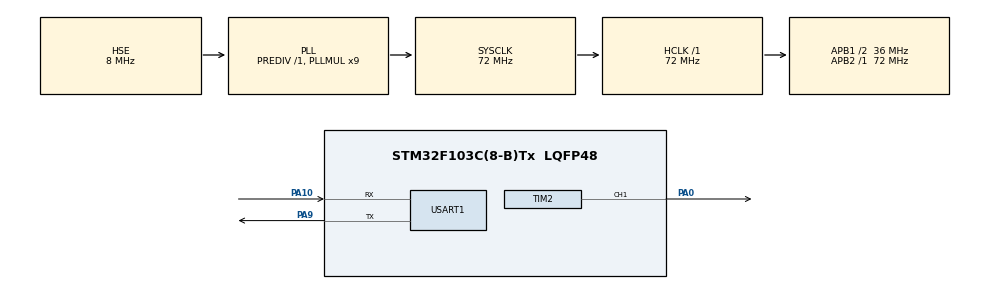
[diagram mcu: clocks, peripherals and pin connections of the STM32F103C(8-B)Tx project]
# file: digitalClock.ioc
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Dma.Request0=TIM2_CH1
Dma.TIM2_CH1.0.Direction=DMA_MEMORY_TO_PERIPH
Dma.TIM2_CH1.0.Instance=DMA1_Channel5
Dma.TIM2_CH1.0.MemDataAlignment=DMA_MDATAALIGN_HALFWORD
Dma.TIM2_CH1.0.MemInc=DMA_MINC_ENABLE
Dma.TIM2_CH1.0.Mode=DMA_NORMAL
Dma.TIM2_CH1.0.PeriphDataAlignment=DMA_PDATAALIGN_HALFWORD
Dma.TIM2_CH1.0.PeriphInc=DMA_PINC_DISABLE
Dma.TIM2_CH1.0.Priority=DMA_PRIORITY_LOW
Mcu.Family=STM32F1
Mcu.Name=STM32F103C(8-B)Tx
Mcu.Package=LQFP48
NVIC.DMA1_Channel5_IRQn=true\:0\:0\:false\:false\:true\:false\:true\:true
NVIC.PriorityGroup=NVIC_PRIORITYGROUP_4
NVIC.TIM2_IRQn=true\:0\:0\:false\:false\:true\:true\:true\:true
PA0-WKUP.Signal=S_TIM2_CH1_ETR
PA10.Mode=Asynchronous
PA10.Signal=USART1_RX
PA13.Mode=Serial_Wire
PA13.Signal=SYS_JTMS-SWDIO
PA14.Mode=Serial_Wire
PA14.Signal=SYS_JTCK-SWCLK
PA9.Mode=Asynchronous
PA9.Signal=USART1_TX
PD0-OSC_IN.Mode=HSE-External-Oscillator
PD0-OSC_IN.Signal=RCC_OSC_IN
PD1-OSC_OUT.Mode=HSE-External-Oscillator
PD1-OSC_OUT.Signal=RCC_OSC_OUT
ProjectManager.HeapSize=0x200
ProjectManager.StackSize=0x400
ProjectManager.TargetToolchain=STM32CubeIDE
RCC.AHBFreq_Value=72000000
RCC.APB1CLKDivider=RCC_HCLK_DIV2
RCC.APB1Freq_Value=36000000
RCC.APB1TimFreq_Value=72000000
RCC.APB2Freq_Value=72000000
RCC.APB2TimFreq_Value=72000000
RCC.HCLKFreq_Value=72000000
RCC.PLLMUL=RCC_PLL_MUL9
RCC.PLLSourceVirtual=RCC_PLLSOURCE_HSE
RCC.SYSCLKFreq_VALUE=72000000
RCC.SYSCLKSource=RCC_SYSCLKSOURCE_PLLCLK
RCC.USBFreq_Value=72000000
SH.S_TIM2_CH1_ETR.0=TIM2_CH1,PWM Generation1 CH1
TIM2.Channel-PWM\ Generation1\ CH1=TIM_CHANNEL_1
TIM2.Period=89
TIM2.Prescaler=1
USART1.VirtualMode=VM_ASYNC
VP_TIM2_VS_ClockSourceINT.Mode=Internal
board=custom

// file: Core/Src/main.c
/* USER CODE BEGIN Header */
/**
  ******************************************************************************
  * @file           : main.c
  * @brief          : Main program body
  ******************************************************************************
  * @attention
  *
  * Copyright (c) 2025 STMicroelectronics.
  * All rights reserved.
  *
  * This software is licensed under terms that can be found in the LICENSE file
  * in the root directory of this software component.
  * If no LICENSE file comes with this software, it is provided AS-IS.
  *
  ******************************************************************************
  */
/* USER CODE END Header */
#include "main.h"

/* USER CODE BEGIN PD */
#define LED_NUM 1
#define LED_LOGICAL_ONE 57 //high
#define LED_LOGICAL_ZERO 28 //low
#define BRIGHTNESS 45 //preset brightness 0-45
/* USER CODE END PD */

TIM_HandleTypeDef htim2;
DMA_HandleTypeDef hdma_tim2_ch1;

UART_HandleTypeDef huart1;

void SystemClock_Config(void);
static void MX_GPIO_Init(void);
static void MX_DMA_Init(void);
static void MX_TIM2_Init(void);
static void MX_USART1_UART_Init(void);

/* USER CODE BEGIN 0 */
uint16_t pulse_arr[24*LED_NUM + 40]; //add bits for reset timing later
uint32_t my_LEDS[LED_NUM][3]; //0 = Green, 1 = Red, 2 = Blue -> buffer for debugging & easier brightness settings

void set_brightness(int brightness, int led_pos){
	float angle = 90-brightness; //degrees
	angle *= M_PI/180; //radians
	my_LEDS[led_pos][0] /= tan(angle);
	my_LEDS[led_pos][1] /= tan(angle);
	my_LEDS[led_pos][2] /= tan(angle);
}

void initiate(){
	reset_all_LEDS();
	for(int i = 0; i < LED_NUM; i++){
		set_LEDS(0, 0, 0, i);
	}
}

void set_LEDS(uint32_t R, uint32_t G, uint32_t B, int led_pos){
	my_LEDS[led_pos][0] = G;
	my_LEDS[led_pos][1] = R;
	my_LEDS[led_pos][2] = B;
	set_brightness(BRIGHTNESS, led_pos);

	uint32_t RGB_bits = my_LEDS[led_pos][0] << 16 | myLEDS[led_pos][1] << 8 | myLEDS[led_pos][2]; //creates a 24 bit number that fits all 3 LEDS (8 bits each)
	for(int i = 0; i < 8; i++){
		if(RGB_bits & 1 << i){ //for all statements below, bitmasks 8 different iterations to isolate one bit
			pulse_arr[i + 24*led_pos] = LED_LOGICAL_ONE;
		}
		else{
			pulse_arr[i + 24*led_pos] = LED_LOGICAL_ZERO;
		}

		if(RGB_bits & 1 << (i + 8)){
			pulse_arr[i + 8 + 24*led_pos] = LED_LOGICAL_ONE;
		}
		else{
			pulse_arr[i + 8 + 24*led_pos] = LED_LOGICAL_ZERO;
		}

		if(RGB_bits & 1 << (i + 16)){
			pulse_arr[i + 16 + 24*led_pos] = LED_LOGICAL_ONE;
		}
		else{
			pulse_arr[i + 16 + 24*led_pos] = LED_LOGICAL_ZERO;
		}
	}
}

//Sets LED pulse values for an LED at a specific index 0 to # of LEDS - 1.
//Able to edit all 24 pulses (or all 3 leds at once) in 8 loops -> # of bits for each RGB
void send_LEDS(){
	HAL_TIM_PWM_Start_DMA(&htim2, TIM_CHANNEL_1, pulse_arr, 24*LED_NUM + 40);
}

//Sets every LED on strip to white color
void set_all_white(){
	for(int i = 0; i < LED_NUM; i++){
		for(int j = 0; j < 8; j++){
			//for all statements below, sets all pulses to logical high
			pulse_arr[j + 24*i] = LED_LOGICAL_ONE;
			pulse_arr[j + 8 + 24*i] = LED_LOGICAL_ONE;
			pulse_arr[j + 16 + 24*i] = LED_LOGICAL_ONE;
		}
	}
}
//Turns every LED off (logical low)
void reset_all_LEDS(){
	for(int i = 0; i < LED_NUM; i++){
		for(int j = 0; j < 8; j++){
			//for all statements below, sets all pulses to logical low
			pulse_arr[j + 24*i] = LED_LOGICAL_ZERO;
			pulse_arr[j + 8 + 24*i] = LED_LOGICAL_ZERO;
			pulse_arr[j + 16 + 24*i] = LED_LOGICAL_ZERO;
		}
	}
}

void HAL_TIM_PWM_PulseFinishedCallback(TIM_HandleTypeDef *htim){
	HAL_TIM_PWM_Stop_DMA(&htim2, TIM_CHANNEL_1);
}

/* USER CODE END 0 */

int main(void)
{

  /* USER CODE BEGIN 1 */
	initiate();

  /* USER CODE END 1 */

  /* MCU Configuration--------------------------------------------------------*/

  /* Reset of all peripherals, Initializes the Flash interface and the Systick. */
  HAL_Init();

  /* Configure the system clock */
  SystemClock_Config();

  /* Initialize all configured peripherals */
  MX_GPIO_Init();
  MX_DMA_Init();
  MX_TIM2_Init();
  MX_USART1_UART_Init();

  /* Infinite loop */
  while (1)
  {

  }
}

void SystemClock_Config(void)
{
  RCC_OscInitTypeDef RCC_OscInitStruct = {0};
  RCC_ClkInitTypeDef RCC_ClkInitStruct = {0};

  /** Initializes the RCC Oscillators according to the specified parameters
  * in the RCC_OscInitTypeDef structure.
  */
  RCC_OscInitStruct.OscillatorType = RCC_OSCILLATORTYPE_HSE;
  RCC_OscInitStruct.HSEState = RCC_HSE_ON;
  RCC_OscInitStruct.HSEPredivValue = RCC_HSE_PREDIV_DIV1;
  RCC_OscInitStruct.HSIState = RCC_HSI_ON;
  RCC_OscInitStruct.PLL.PLLState = RCC_PLL_ON;
  RCC_OscInitStruct.PLL.PLLSource = RCC_PLLSOURCE_HSE;
  RCC_OscInitStruct.PLL.PLLMUL = RCC_PLL_MUL9;
  if (HAL_RCC_OscConfig(&RCC_OscInitStruct) != HAL_OK)
  {
    Error_Handler();
  }

  /** Initializes the CPU, AHB and APB buses clocks
  */
  RCC_ClkInitStruct.ClockType = RCC_CLOCKTYPE_HCLK|RCC_CLOCKTYPE_SYSCLK
                              |RCC_CLOCKTYPE_PCLK1|RCC_CLOCKTYPE_PCLK2;
  RCC_ClkInitStruct.SYSCLKSource = RCC_SYSCLKSOURCE_PLLCLK;
  RCC_ClkInitStruct.AHBCLKDivider = RCC_SYSCLK_DIV1;
  RCC_ClkInitStruct.APB1CLKDivider = RCC_HCLK_DIV2;
  RCC_ClkInitStruct.APB2CLKDivider = RCC_HCLK_DIV1;

  if (HAL_RCC_ClockConfig(&RCC_ClkInitStruct, FLASH_LATENCY_2) != HAL_OK)
  {
    Error_Handler();
  }
}

static void MX_TIM2_Init(void)
{

  TIM_ClockConfigTypeDef sClockSourceConfig = {0};
  TIM_MasterConfigTypeDef sMasterConfig = {0};
  TIM_OC_InitTypeDef sConfigOC = {0};

  htim2.Instance = TIM2;
  htim2.Init.Prescaler = 1;
  htim2.Init.CounterMode = TIM_COUNTERMODE_UP;
  htim2.Init.Period = 89;
  htim2.Init.ClockDivision = TIM_CLOCKDIVISION_DIV1;
  htim2.Init.AutoReloadPreload = TIM_AUTORELOAD_PRELOAD_DISABLE;
  if (HAL_TIM_Base_Init(&htim2) != HAL_OK)
  {
    Error_Handler();
  }
  sClockSourceConfig.ClockSource = TIM_CLOCKSOURCE_INTERNAL;
  if (HAL_TIM_ConfigClockSource(&htim2, &sClockSourceConfig) != HAL_OK)
  {
    Error_Handler();
  }
  if (HAL_TIM_PWM_Init(&htim2) != HAL_OK)
  {
    Error_Handler();
  }
  sMasterConfig.MasterOutputTrigger = TIM_TRGO_RESET;
  sMasterConfig.MasterSlaveMode = TIM_MASTERSLAVEMODE_DISABLE;
  if (HAL_TIMEx_MasterConfigSynchronization(&htim2, &sMasterConfig) != HAL_OK)
  {
    Error_Handler();
  }
  sConfigOC.OCMode = TIM_OCMODE_PWM1;
  sConfigOC.Pulse = 0;
  sConfigOC.OCPolarity = TIM_OCPOLARITY_HIGH;
  sConfigOC.OCFastMode = TIM_OCFAST_DISABLE;
  if (HAL_TIM_PWM_ConfigChannel(&htim2, &sConfigOC, TIM_CHANNEL_1) != HAL_OK)
  {
    Error_Handler();
  }
  HAL_TIM_MspPostInit(&htim2);

}

static void MX_USART1_UART_Init(void)
{

  huart1.Instance = USART1;
  huart1.Init.BaudRate = 115200;
  huart1.Init.WordLength = UART_WORDLENGTH_8B;
  huart1.Init.StopBits = UART_STOPBITS_1;
  huart1.Init.Parity = UART_PARITY_NONE;
  huart1.Init.Mode = UART_MODE_TX_RX;
  huart1.Init.HwFlowCtl = UART_HWCONTROL_NONE;
  huart1.Init.OverSampling = UART_OVERSAMPLING_16;
  if (HAL_UART_Init(&huart1) != HAL_OK)
  {
    Error_Handler();
  }

}

static void MX_DMA_Init(void)
{

  /* DMA controller clock enable */
  __HAL_RCC_DMA1_CLK_ENABLE();

  /* DMA interrupt init */
  /* DMA1_Channel5_IRQn interrupt configuration */
  HAL_NVIC_SetPriority(DMA1_Channel5_IRQn, 0, 0);
  HAL_NVIC_EnableIRQ(DMA1_Channel5_IRQn);

}

static void MX_GPIO_Init(void)
{

  /* GPIO Ports Clock Enable */
  __HAL_RCC_GPIOD_CLK_ENABLE();
  __HAL_RCC_GPIOA_CLK_ENABLE();

}

void Error_Handler(void)
{
  __disable_irq();
  while (1)
  {
  }
}
